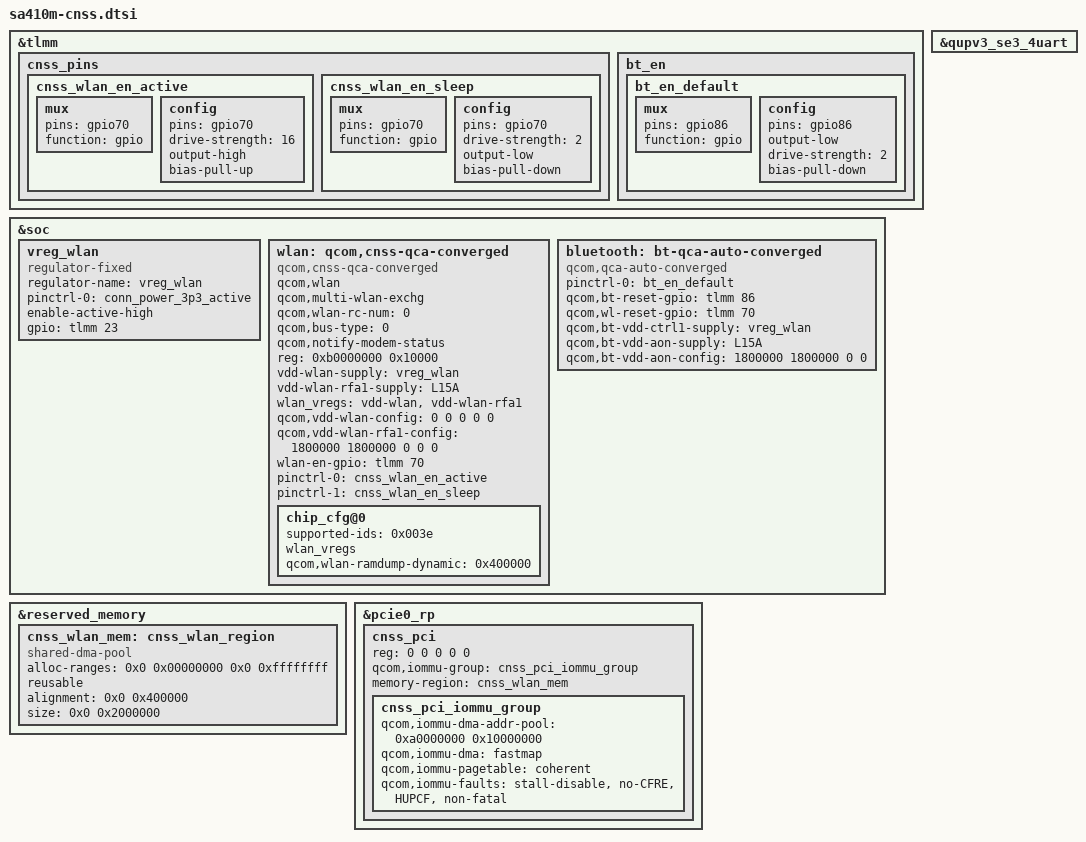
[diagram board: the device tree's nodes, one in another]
&tlmm {
	cnss_pins {
		cnss_wlan_en_active: cnss_wlan_en_active {
			mux {
				pins = "gpio70";
				function = "gpio";
			};

			config {
				pins = "gpio70";
				drive-strength = <16>;
				output-high;
				bias-pull-up;
			};
		};

		cnss_wlan_en_sleep: cnss_wlan_en_sleep {
			mux {
				pins = "gpio70";
				function = "gpio";
			};

			config {
				pins = "gpio70";
				drive-strength = <2>;
				output-low;
				bias-pull-down;
			};
		};
	};

	bt_en {
		bt_en_default: bt_en_default {
			mux {
				pins = "gpio86";
				function = "gpio";
			};

			config {
				pins = "gpio86";
				output-low;
				drive-strength = <2>;
				bias-pull-down;
			};
		};
	};
};

&soc {
	/* Rome 3.3V supply */
	vreg_wlan: vreg_wlan {
		compatible = "regulator-fixed";
		regulator-name = "vreg_wlan";
		pinctrl-names = "default";
		pinctrl-0 = <&conn_power_3p3_active>;
		enable-active-high;
		gpio = <&tlmm 23 0>;
	};
};

&reserved_memory {
	cnss_wlan_mem: cnss_wlan_region {
		compatible = "shared-dma-pool";
		alloc-ranges = <0x0 0x00000000 0x0 0xffffffff>;
		reusable;
		alignment = <0x0 0x400000>;
		size = <0x0 0x2000000>;
	};
};

&soc {
	wlan: qcom,cnss-qca-converged {
		compatible = "qcom,cnss-qca-converged";
		qcom,wlan;
		qcom,multi-wlan-exchg;
		qcom,wlan-rc-num = <0>;
		qcom,bus-type=<0>;
		qcom,notify-modem-status;

		reg = <0xb0000000 0x10000>;
		reg-names = "smmu_iova_ipa";

		vdd-wlan-supply = <&vreg_wlan>;
		vdd-wlan-rfa1-supply = <&L15A>;

		wlan_vregs = "vdd-wlan", "vdd-wlan-rfa1";
		qcom,vdd-wlan-config = <0 0 0 0 0>;
		qcom,vdd-wlan-rfa1-config = <1800000 1800000 0 0 0>;
		wlan-en-gpio = <&tlmm 70 0>;
		pinctrl-names = "wlan_en_active", "wlan_en_sleep";
		pinctrl-0 = <&cnss_wlan_en_active>;
		pinctrl-1 = <&cnss_wlan_en_sleep>;

		chip_cfg@0 {
			supported-ids = <0x003e>;
			wlan_vregs;
			qcom,wlan-ramdump-dynamic = <0x400000>;
		};
	};
};

&pcie0_rp {
	#address-cells = <5>;
	#size-cells = <0>;
	cnss_pci: cnss_pci {
		reg = <0 0 0 0 0>;
		qcom,iommu-group = <&cnss_pci_iommu_group>;
		memory-region = <&cnss_wlan_mem>;

		#address-cells = <1>;
		#size-cells = <1>;

		cnss_pci_iommu_group: cnss_pci_iommu_group {
			qcom,iommu-dma-addr-pool = <0xa0000000 0x10000000>;
			qcom,iommu-dma = "fastmap";
			qcom,iommu-pagetable = "coherent";
			qcom,iommu-faults = "stall-disable", "no-CFRE", "HUPCF",
					    "non-fatal";
		};
	};
};

&soc {
	bluetooth: bt-qca-auto-converged {
		compatible = "qcom,qca-auto-converged";
		pinctrl-names = "default";
		pinctrl-0 = <&bt_en_default>;
		qcom,bt-reset-gpio = <&tlmm 86 0>;
		qcom,wl-reset-gpio = <&tlmm 70 0>;
		qcom,bt-vdd-ctrl1-supply = <&vreg_wlan>;
		qcom,bt-vdd-aon-supply  = <&L15A>;
		qcom,bt-vdd-aon-config  = <1800000 1800000 0 0>;
	};
};

&qupv3_se3_4uart {
	status = "ok";
};
